# HK32L0xx register map
Vendor: HKMicroChip Ltd.; Series: HK32L0xx; File version: 1.3
CPU: CM0 r0p0, little endian, no MPU, no FPU, 3 interrupt priority bits
Registers are 32-bit, read-write, reset 0x0 unless marked. A register's access mark holds for its fields unless they carry their own. Offsets are from the block's base; [hi:lo] are bit positions; {n}, {i} and the like mark numbered series.

## DMA
Base 0x40020000
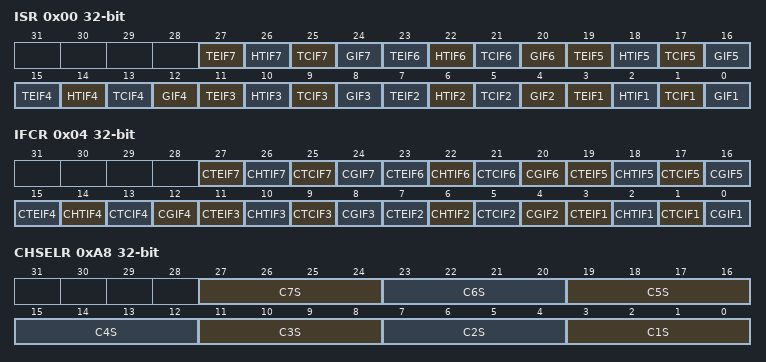
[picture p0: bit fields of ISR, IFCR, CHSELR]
0x00 ISR ro
  [4n-1] TEIF{n} (n=1..7) — Channel x transfer error flag
  [4n-2] HTIF{n} (n=1..7) — Channel x half transfer flag
  [4n-3] TCIF{n} (n=1..7) — Channel x transfer complete flag
  [4n-4] GIF{n} (n=1..7) — Channel x global interrupt flag
0x04 IFCR wo
  [4n-1] CTEIF{n} (n=1..7) — Channel x transfer error clear
  [4n-2] CHTIF{n} (n=1..7) — Channel x half transfer clear
  [4n-3] CTCIF{n} (n=1..7) — Channel x transfer complete clear
  [4n-4] CGIF{n} (n=1..7) — Channel x global interrupt clear
0xA8 CHSELR
  [4n-1:4n-4] C{n}S (n=1..7) — channel {n} select

## DMA_Channel1
Base 0x40020008
Same registers: DMA_Channel2 0x4002001C, DMA_Channel3 0x40020030, DMA_Channel4 0x40020044, DMA_Channel5 0x40020058, DMA_Channel6 0x4002006C, DMA_Channel7 0x40020080
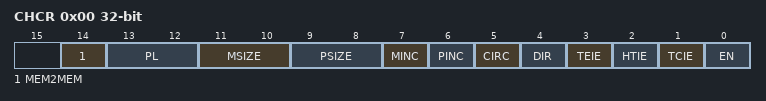
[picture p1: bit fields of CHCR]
0x00 CHCR
  [14] MEM2MEM — Memory to memory mode
  [13:12] PL — Channel priority level
  [11:10] MSIZE — Memory size
  [9:8] PSIZE — Peripheral size
  [7] MINC — Memory increment mode
  [6] PINC — Peripheral increment mode
  [5] CIRC — Circular mode
  [4] DIR — Data transfer direction
  [3] TEIE — Transfer error interrupt enable
  [2] HTIE — Half transfer interrupt enable
  [1] TCIE — Transfer complete interrupt enable
  [0] EN — Channel enable
0x04 CHDTR
  [15:0] NDT — Number of data to transfer
0x08 CHPAR
  [31:0] PA — Peripheral address
0x0C CHMAR
  [31:0] MA — Memory address

## EXTI
Base 0x40010400
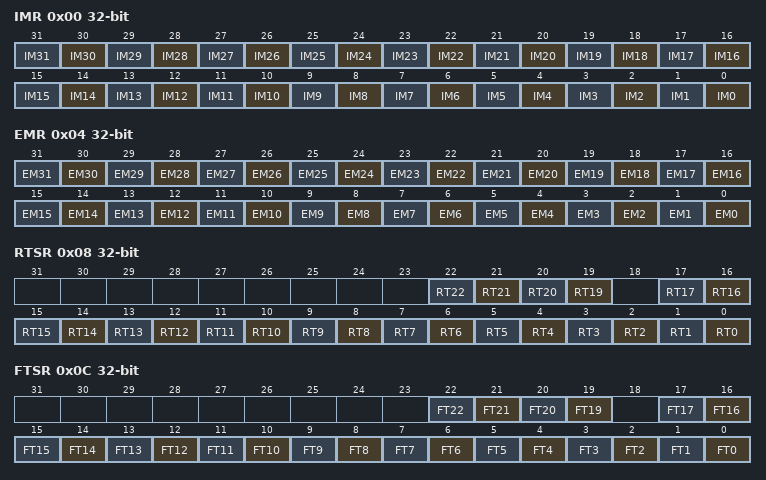
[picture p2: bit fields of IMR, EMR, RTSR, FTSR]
0x00 IMR
  [n] IM{n} (n=0..31) — Interrupt mask on line x
0x04 EMR
  [n] EM{n} (n=0..31) — Event mask on line x
0x08 RTSR
  [n] RT{n} (n=19..22) — Rising trigger event configuration bit of line x
  [n] RT{n} (n=0..17) — Rising trigger event configuration bit of line x
0x0C FTSR
  [n] FT{n} (n=19..22) — Falling trigger event configuration bit of line x
  [n] FT{n} (n=0..17) — Falling trigger event configuration bit of line x
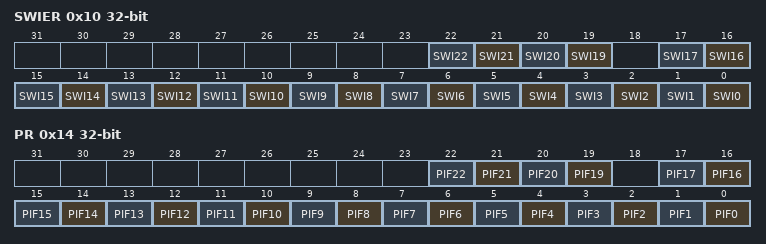
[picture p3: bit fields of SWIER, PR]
0x10 SWIER
  [n] SWI{n} (n=19..22) — Software interrupt on line x
  [n] SWI{n} (n=0..17) — Software interrupt on line x
0x14 PR
  [n] PIF{n} (n=19..22) — Pending interrupt flag on line x
  [n] PIF{n} (n=0..17) — Pending interrupt flag on line x

## TIM14
Base 0x40002000
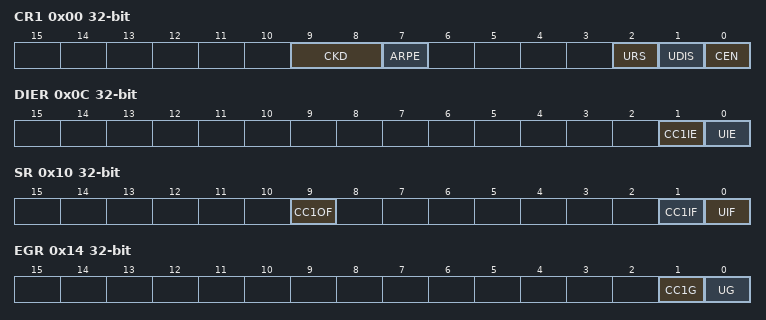
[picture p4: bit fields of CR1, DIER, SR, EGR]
0x00 CR1
  [9:8] CKD — Clock division
  [7] ARPE — Auto-reload preload enable
  [2] URS — Update request source
  [1] UDIS — Update disable
  [0] CEN — Counter enable
0x0C DIER
  [1] CC1IE — Capture/Compare 1 interrupt enable
  [0] UIE — Update interrupt enable
0x10 SR
  [9] CC1OF — Capture/Compare 1 overcapture flag
  [1] CC1IF — Capture/Compare 1 interrupt flag
  [0] UIF — Update interrupt flag
0x14 EGR wo
  [1] CC1G — Capture/Compare 1 generation
  [0] UG — Update generation
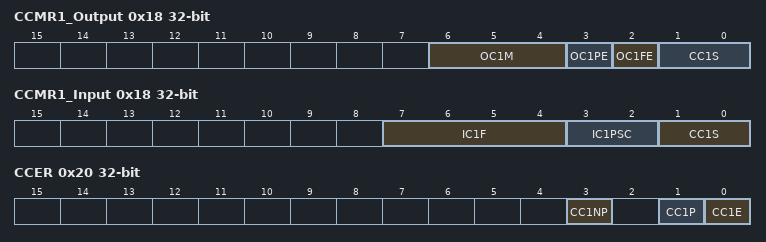
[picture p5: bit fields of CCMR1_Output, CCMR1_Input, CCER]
0x18 CCMR1_Output
  [6:4] OC1M — Output compare 1 mode
  [3] OC1PE — Output compare 1 preload enable
  [2] OC1FE — Output compare 1 fast enable
  [1:0] CC1S — Capture/Compare 1 selection
0x18 CCMR1_Input (alternate view of CCMR1_Output)
  [7:4] IC1F — Input capture 1 fliter
  [3:2] IC1PSC — Input capture 1 prescaler
  [1:0] CC1S — Capture/Compare 1 selection
0x20 CCER
  [3] CC1NP — Capture/Compare 1 complementary output Polarity
  [1] CC1P — Capture/Compare 1 output Polarity
  [0] CC1E — Capture/Compare 1 output enable
0x24 CNT
  [15:0] CNT — Counter value
0x28 PSC
  [15:0] PSC — Prescaler value
0x2C ARR reset 0xFFFF
  [15:0] ARR — Auto-reload value
0x34 CCR1
  [15:0] CCR1 — Capture/Compare 1 value
0x50 OR
  [0] TI1_RMP — Timer Input 1 remap

## TIM15
Base 0x40014000
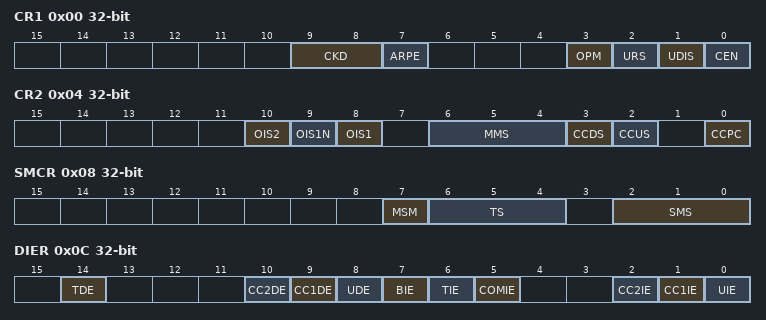
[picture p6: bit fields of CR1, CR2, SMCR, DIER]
0x00 CR1
  [9:8] CKD — Clock division
  [7] ARPE — Auto-reload preload enable
  [3] OPM — One pulse mode
  [2] URS — Update request source
  [1] UDIS — Update disable
  [0] CEN — Counter enable
0x04 CR2
  [10] OIS2 — Output Idle state 2
  [9] OIS1N — Output Idle state 1
  [8] OIS1 — Output Idle state 1
  [6:4] MMS — Master mode selection
  [3] CCDS — Capture/Compare DMA selection
  [2] CCUS — Capture/Compare control update selection
  [0] CCPC — Capture/Compare preloaded control
0x08 SMCR
  [7] MSM — Master/Slave mode
  [6:4] TS — Trigger selection
  [2:0] SMS — Slave mode selection
0x0C DIER
  [14] TDE — Trigger DMA request enable
  [10] CC2DE — Capture/Compare 2 DMA request enable
  [9] CC1DE — Capture/Compare 1 DMA request enable
  [8] UDE — Update DMA request enable
  [7] BIE — Break interrupt enable
  [6] TIE — Trigger interrupt enable
  [5] COMIE — COM interrupt enable
  [2] CC2IE — Capture/Compare 2 interrupt enable
  [1] CC1IE — Capture/Compare 1 interrupt enable
  [0] UIE — Update interrupt enable
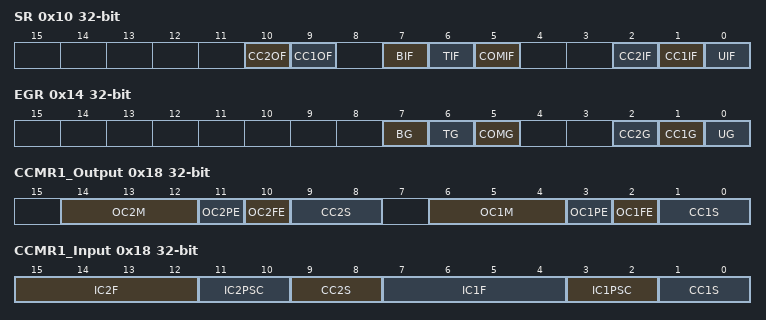
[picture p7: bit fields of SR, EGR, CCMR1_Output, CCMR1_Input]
0x10 SR
  [10] CC2OF — Capture/Compare 2 overcapture flag
  [9] CC1OF — Capture/Compare 1 overcapture flag
  [7] BIF — Break interrupt flag
  [6] TIF — Trigger interrupt flag
  [5] COMIF — COM interrupt flag
  [2] CC2IF — Capture/Compare 2 interrupt flag
  [1] CC1IF — Capture/Compare 1 interrupt flag
  [0] UIF — Update interrupt flag
0x14 EGR wo
  [7] BG — Break generation
  [6] TG — Trigger generation
  [5] COMG — Capture/Compare control update generation
  [2] CC2G — Capture/Compare 2 generation
  [1] CC1G — Capture/Compare 1 generation
  [0] UG — Update generation
0x18 CCMR1_Output
  [14:12] OC2M — Output Compare 2 mode
  [11] OC2PE — Output Compare 2 preload enable
  [10] OC2FE — Output Compare 2 fast enable
  [9:8] CC2S — Capture/Compare 2 selection
  [6:4] OC1M — Output Compare 1 mode
  [3] OC1PE — Output Compare 1 preload enable
  [2] OC1FE — Output Compare 1 fast enable
  [1:0] CC1S — Capture/Compare 1 selection
0x18 CCMR1_Input (alternate view of CCMR1_Output)
  [15:12] IC2F — Input capture 2 filter
  [11:10] IC2PSC — Input capture 2 prescaler
  [9:8] CC2S — Capture/Compare 2 selection
  [7:4] IC1F — Input capture 1 filter
  [3:2] IC1PSC — Input capture 1 prescaler
  [1:0] CC1S — Capture/Compare 1 Selection
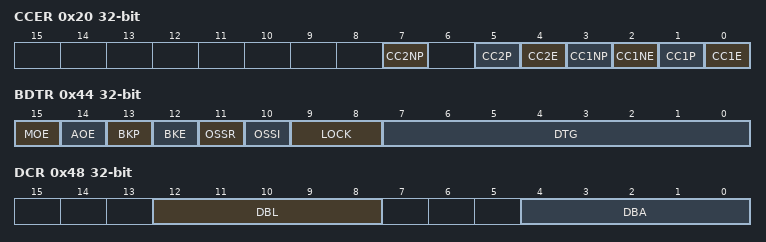
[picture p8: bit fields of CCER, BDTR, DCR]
0x20 CCER
  [7] CC2NP — Capture/Compare 2 complementary output polarity
  [5] CC2P — Capture/Compare 2 output polarity
  [4] CC2E — Capture/Compare 2 output enable
  [3] CC1NP — Capture/Compare 1 complementary output polarity
  [2] CC1NE — Capture/Compare 1 complementary output enable
  [1] CC1P — Capture/Compare 1 output polarity
  [0] CC1E — Capture/Compare 1 output enable
0x24 CNT
  [15:0] CNT — Counter value
0x28 PSC
  [15:0] PSC — Pre-scaler value
0x2C ARR reset 0xFFFF
  [15:0] ARR — Auto-reloaded value
0x30 RCR
  [7:0] REP — Repetition counter value
0x34 CCR1
  [15:0] CCR1 — Capture/Compare 1 value
0x38 CCR2
  [15:0] CCR2 — Capture/Compare 2 value
0x44 BDTR
  [15] MOE — Main output enable
  [14] AOE — Automatic output enable
  [13] BKP — Break polarity
  [12] BKE — Break enable
  [11] OSSR — Off-state selection for Run mode
  [10] OSSI — Off-state selection for Idle mode
  [9:8] LOCK — Lock configuration
  [7:0] DTG — Dead-time generator setup
0x48 DCR
  [12:8] DBL — DMA burst length
  [4:0] DBA — DMA base address
0x4C DMAR
  [15:0] DMAB — DMA register for burst accesses
